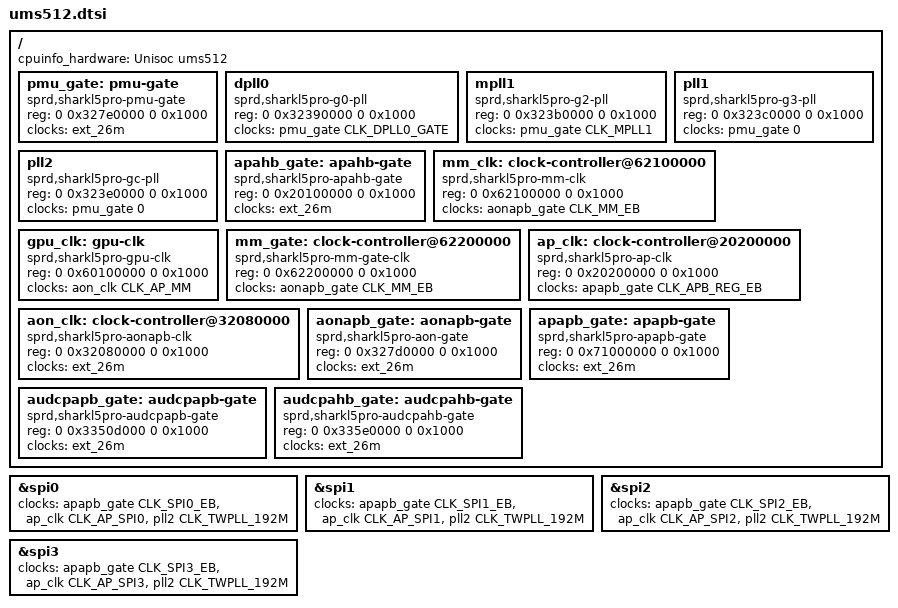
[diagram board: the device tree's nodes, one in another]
/*
 * Spreadtrum ums512 board DTS file
 *
 * Copyright (C) 2019, Spreadtrum Communications Inc.
 *
 * This file is licensed under a dual GPLv2 or X11 license.
 */

#include "sharkl5Pro.dtsi"

/ {
	cpuinfo_hardware = "Unisoc ums512";

	pmu_gate: pmu-gate {
		compatible = "sprd,sharkl5pro-pmu-gate";
		/*sprd,syscon = <&pmu_apb_regs>;*/ /* 0x327e0000 */
		reg = <0 0x327e0000 0 0x1000>;
		clocks = <&ext_26m>;
		#clock-cells = <1>;
	};

	dpll0: dpll0 {
		compatible = "sprd,sharkl5pro-g0-pll";
		/*sprd,syscon = <&anlg_phy_g0_regs>;*/ /* 0x32390000 */
		reg = <0 0x32390000 0 0x1000>;
		clocks = <&pmu_gate CLK_DPLL0_GATE>;
		#clock-cells = <1>;
	};

	mpll1: mpll1 {
		compatible = "sprd,sharkl5pro-g2-pll";
		/*sprd,syscon = <&anlg_phy_g2_regs>;*/ /* 0x323b0000 */
		reg = <0 0x323b0000 0 0x1000>;
		clocks = <&pmu_gate CLK_MPLL1>;
		#clock-cells = <1>;
	};

	pll1: pll1 {
		compatible = "sprd,sharkl5pro-g3-pll";
		/*sprd,syscon = <&anlg_phy_g3_regs>;*/ /* 0x323c0000 */
		reg = <0 0x323c0000 0 0x1000>;
		clocks = <&pmu_gate 0>;
		#clock-cells = <1>;
	};

	pll2: pll2 {
		compatible = "sprd,sharkl5pro-gc-pll";
		/*sprd,syscon = <&anlg_phy_gc_regs>;*/ /* 0x323e0000 */
		reg = <0 0x323e0000 0 0x1000>;
		clocks = <&pmu_gate 0>;
		#clock-cells = <1>;
	};

	apahb_gate: apahb-gate {
		compatible = "sprd,sharkl5pro-apahb-gate";
		/*sprd,syscon = <&ap_ahb_regs>;*/ /* 0x20100000 */
		reg = <0 0x20100000 0 0x1000>;
		clocks = <&ext_26m>;
		#clock-cells = <1>;
	};

	mm_clk: clock-controller@62100000 {
		compatible = "sprd,sharkl5pro-mm-clk";
		reg = <0 0x62100000 0 0x1000>;
		clocks = <&aonapb_gate CLK_MM_EB>;
		#clock-cells = <1>;
	};

	gpu_clk: gpu-clk {
		compatible = "sprd,sharkl5pro-gpu-clk";
		/*sprd,syscon = <&gpu_apb_regs>;*/
		reg = <0 0x60100000 0 0x1000>;
		clocks = <&aon_clk CLK_AP_MM>;
		#clock-cells = <1>;
	};

	mm_gate: clock-controller@62200000 {
		compatible = "sprd,sharkl5pro-mm-gate-clk";
		/*sprd,syscon = <&mm_ahb_regs>;*/
		reg = <0 0x62200000 0 0x1000>;
		clocks = <&aonapb_gate CLK_MM_EB>;
		#clock-cells = <1>;
	};

	ap_clk: clock-controller@20200000 {
		compatible = "sprd,sharkl5pro-ap-clk";
		reg = <0 0x20200000 0 0x1000>;
		clocks = <&apapb_gate CLK_APB_REG_EB>;
		#clock-cells = <1>;
	};

	aon_clk: clock-controller@32080000 {
		compatible = "sprd,sharkl5pro-aonapb-clk";
		reg = <0 0x32080000 0 0x1000>;
		clocks = <&ext_26m>;
		#clock-cells = <1>;
	};

	aonapb_gate: aonapb-gate {
		compatible = "sprd,sharkl5pro-aon-gate";
		/*sprd,syscon = <&aon_apb_regs>;*/ /* 0x327d0000 */
		reg = <0 0x327d0000 0 0x1000>;
		clocks = <&ext_26m>;
		#clock-cells = <1>;
	};

	apapb_gate: apapb-gate {
		compatible = "sprd,sharkl5pro-apapb-gate";
		/*sprd,syscon = <&ap_apb_regs>;*/ /* 0x71000000 */
		reg = <0 0x71000000 0 0x1000>;
		clocks = <&ext_26m>;
		#clock-cells = <1>;
	};

	audcpapb_gate: audcpapb-gate {
		compatible = "sprd,sharkl5pro-audcpapb-gate";
		/*sprd,syscon = <&audcp_apb_regs>;*/ /* 0x3350d000 */
		reg = <0 0x3350d000 0 0x1000>;
		clocks = <&ext_26m>;
		#clock-cells = <1>;
	};

	audcpahb_gate: audcpahb-gate {
		compatible = "sprd,sharkl5pro-audcpahb-gate";
		/*sprd,syscon = <&audcp_ahb_regs>;*/ /* 0x335e0000 */
		reg = <0 0x335e0000 0 0x1000>;
		clocks = <&ext_26m>;
		#clock-cells = <1>;
	};
};

&spi0 {
	clock-names = "enable", "spi", "source";
	clocks = <&apapb_gate CLK_SPI0_EB>,
	<&ap_clk CLK_AP_SPI0>, <&pll2 CLK_TWPLL_192M>;
};

&spi1 {
	clock-names = "enable", "spi", "source";
	clocks = <&apapb_gate CLK_SPI1_EB>,
	<&ap_clk CLK_AP_SPI1>, <&pll2 CLK_TWPLL_192M>;
};

&spi2 {
	clock-names = "enable", "spi", "source";
	clocks = <&apapb_gate CLK_SPI2_EB>,
	<&ap_clk CLK_AP_SPI2>, <&pll2 CLK_TWPLL_192M>;
};

&spi3 {
	clock-names = "enable", "spi", "source";
	clocks = <&apapb_gate CLK_SPI3_EB>,
	<&ap_clk CLK_AP_SPI3>, <&pll2 CLK_TWPLL_192M>;
};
